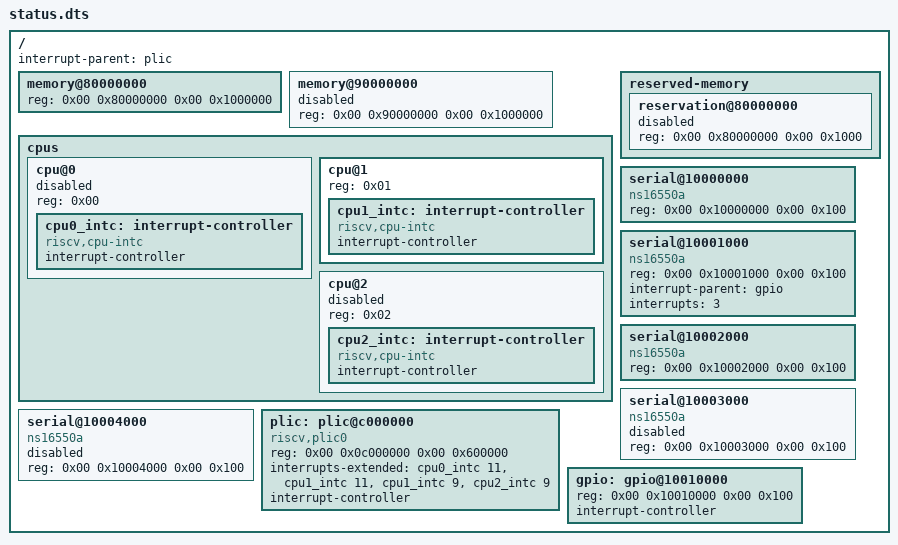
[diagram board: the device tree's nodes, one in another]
/*
 * A small Devicetree for the host tests of the 'status' property.
 * Nodes whose 'status' isn't "okay" or "ok" must be skipped.
 * It also has cases that QEMU's Devicetree doesn't: PLIC contexts that
 * aren't 'hart * 2 + 1', and an inherited 'interrupt-parent'.
 *
 * status.dtb is built from this file, and both are committed. After changing
 * this file, rebuild it from this directory with:
 *   dtc -I dts -O dtb -o status.dtb status.dts
 */

/dts-v1/;

/ {
	#address-cells = <2>;
	#size-cells = <2>;
	interrupt-parent = <&plic>;

	memory@80000000 {
		device_type = "memory";
		reg = <0x00 0x80000000 0x00 0x1000000>;
	};

	memory@90000000 {
		device_type = "memory";
		reg = <0x00 0x90000000 0x00 0x1000000>;
		status = "disabled";
	};

	cpus {
		#address-cells = <1>;
		#size-cells = <0>;

		cpu@0 {
			device_type = "cpu";
			reg = <0x00>;
			status = "disabled";

			cpu0_intc: interrupt-controller {
				compatible = "riscv,cpu-intc";
				interrupt-controller;
				#address-cells = <0>;
				#interrupt-cells = <1>;
			};
		};

		cpu@1 {
			device_type = "cpu";
			reg = <0x01>;
			status = "okay";

			cpu1_intc: interrupt-controller {
				compatible = "riscv,cpu-intc";
				interrupt-controller;
				#address-cells = <0>;
				#interrupt-cells = <1>;
			};
		};

		/*
		 * A disabled hart after an available one, so that its
		 * 'riscv,cpu-intc' isn't taken for hart 1's.
		 */
		cpu@2 {
			device_type = "cpu";
			reg = <0x02>;
			status = "disabled";

			cpu2_intc: interrupt-controller {
				compatible = "riscv,cpu-intc";
				interrupt-controller;
				#address-cells = <0>;
				#interrupt-cells = <1>;
			};
		};
	};

	reserved-memory {
		#address-cells = <2>;
		#size-cells = <2>;
		ranges;

		reservation@80000000 {
			reg = <0x00 0x80000000 0x00 0x1000>;
			status = "disabled";
		};
	};

	serial@10000000 {
		compatible = "ns16550a";
		reg = <0x00 0x10000000 0x00 0x100>;
		status = "okay";
	};

	serial@10001000 {
		compatible = "ns16550a";
		reg = <0x00 0x10001000 0x00 0x100>;
		status = "ok";
		interrupt-parent = <&gpio>;
		interrupts = <3>;
	};

	serial@10002000 {
		compatible = "ns16550a";
		reg = <0x00 0x10002000 0x00 0x100>;
	};

	serial@10003000 {
		compatible = "ns16550a";
		reg = <0x00 0x10003000 0x00 0x100>;
		status = "disabled";
	};

	serial@10004000 {
		compatible = "ns16550a";
		reg = <0x00 0x10004000 0x00 0x100>;
		status = "fail";
	};

	/*
	 * Hart 0 only has a machine-mode context, like the monitor core on some
	 * boards, so hart 1's supervisor-mode context is 2, not 3. Context 3
	 * belongs to the disabled hart 2.
	 */
	plic: plic@c000000 {
		compatible = "riscv,plic0";
		phandle = <0x20>;
		reg = <0x00 0x0c000000 0x00 0x600000>;
		interrupts-extended = <&cpu0_intc 11 &cpu1_intc 11 &cpu1_intc 9
				       &cpu2_intc 9>;
		interrupt-controller;
		#address-cells = <0>;
		#interrupt-cells = <1>;
	};

	/*
	 * An interrupt controller the parser doesn't recognise, for the second
	 * UART's own 'interrupt-parent'.
	 */
	gpio: gpio@10010000 {
		reg = <0x00 0x10010000 0x00 0x100>;
		phandle = <0x21>;
		interrupt-controller;
		#address-cells = <0>;
		#interrupt-cells = <1>;
	};
};
